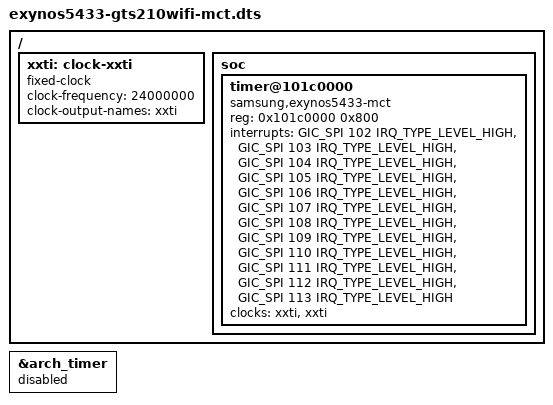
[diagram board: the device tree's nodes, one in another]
// SPDX-License-Identifier: GPL-2.0
/*
 * M1 variant: tick from the Exynos MCT (SPI interrupts) instead of the
 * ARM arch timer, in case the secure firmware owns the PPIs.
 */
#include "exynos5433-gts210wifi.dts"

&arch_timer {
	status = "disabled";
};

/ {
	xxti: clock-xxti {
		compatible = "fixed-clock";
		#clock-cells = <0>;
		clock-frequency = <24000000>;
		clock-output-names = "xxti";
	};

	soc {
		timer@101c0000 {
			compatible = "samsung,exynos5433-mct", "samsung,exynos4210-mct";
			reg = <0x101c0000 0x800>;
			interrupts = <GIC_SPI 102 IRQ_TYPE_LEVEL_HIGH>,
				     <GIC_SPI 103 IRQ_TYPE_LEVEL_HIGH>,
				     <GIC_SPI 104 IRQ_TYPE_LEVEL_HIGH>,
				     <GIC_SPI 105 IRQ_TYPE_LEVEL_HIGH>,
				     <GIC_SPI 106 IRQ_TYPE_LEVEL_HIGH>,
				     <GIC_SPI 107 IRQ_TYPE_LEVEL_HIGH>,
				     <GIC_SPI 108 IRQ_TYPE_LEVEL_HIGH>,
				     <GIC_SPI 109 IRQ_TYPE_LEVEL_HIGH>,
				     <GIC_SPI 110 IRQ_TYPE_LEVEL_HIGH>,
				     <GIC_SPI 111 IRQ_TYPE_LEVEL_HIGH>,
				     <GIC_SPI 112 IRQ_TYPE_LEVEL_HIGH>,
				     <GIC_SPI 113 IRQ_TYPE_LEVEL_HIGH>;
			clocks = <&xxti>, <&xxti>;
			clock-names = "fin_pll", "mct";
		};
	};
};
